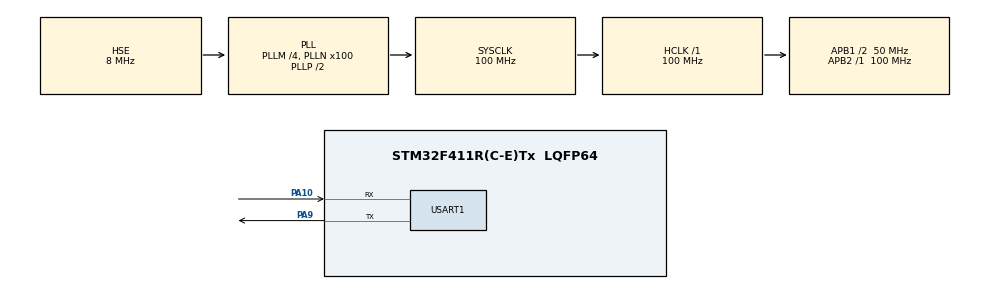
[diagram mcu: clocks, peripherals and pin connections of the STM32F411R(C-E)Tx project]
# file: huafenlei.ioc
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Mcu.Family=STM32F4
Mcu.Name=STM32F411R(C-E)Tx
Mcu.Package=LQFP64
NVIC.PriorityGroup=NVIC_PRIORITYGROUP_4
NVIC.USART1_IRQn=true\:0\:0\:false\:false\:true\:true\:true\:true
PA10.Mode=Asynchronous
PA10.Signal=USART1_RX
PA13.Mode=Serial_Wire
PA13.Signal=SYS_JTMS-SWDIO
PA14.Mode=Serial_Wire
PA14.Signal=SYS_JTCK-SWCLK
PA9.Mode=Asynchronous
PA9.Signal=USART1_TX
PH0\ -\ OSC_IN.Mode=HSE-External-Oscillator
PH0\ -\ OSC_IN.Signal=RCC_OSC_IN
PH1\ -\ OSC_OUT.Mode=HSE-External-Oscillator
PH1\ -\ OSC_OUT.Signal=RCC_OSC_OUT
ProjectManager.HeapSize=0x800
ProjectManager.StackSize=0x800
ProjectManager.TargetToolchain=MDK-ARM V5.27
RCC.48MHZClocksFreq_Value=50000000
RCC.AHBFreq_Value=100000000
RCC.APB1CLKDivider=RCC_HCLK_DIV2
RCC.APB1Freq_Value=50000000
RCC.APB1TimFreq_Value=100000000
RCC.APB2Freq_Value=100000000
RCC.APB2TimFreq_Value=100000000
RCC.CortexFreq_Value=100000000
RCC.HCLKFreq_Value=100000000
RCC.HSE_VALUE=8000000
RCC.HSI_VALUE=16000000
RCC.LSE_VALUE=32768
RCC.PLLM=4
RCC.PLLN=100
RCC.PLLSourceVirtual=RCC_PLLSOURCE_HSE
RCC.SYSCLKFreq_VALUE=100000000
RCC.SYSCLKSource=RCC_SYSCLKSOURCE_PLLCLK
RCC.VCOOutputFreq_Value=200000000
STMicroelectronics.X-CUBE-AI.10.2.0.ActivationBufferSizeList=2084
STMicroelectronics.X-CUBE-AI.10.2.0.ActivationBuffers=pool0
STMicroelectronics.X-CUBE-AI.10.2.0.ActivationNames=pool0
STMicroelectronics.X-CUBE-AI.10.2.0.ActivationSizes=AI_NETWORK_DATA_ACTIVATION_1_SIZE
STMicroelectronics.X-CUBE-AI.10.2.0.HeapSize=0x800
STMicroelectronics.X-CUBE-AI.10.2.0.InternalRamActivationBufferMaxSize=AI_NETWORK_DATA_ACTIVATIONS_SIZE
STMicroelectronics.X-CUBE-AI.10.2.0.LatestDirectoryUsed-87fcd24d699568835ba487657c0ed03bb26ed7f382c4cfd018235e4fa8d2ef7a=D\:\\
STMicroelectronics.X-CUBE-AI.10.2.0.MaximumNumberOfInputLayer=1
STMicroelectronics.X-CUBE-AI.10.2.0.MaximumNumberOfOutputLayer=1
STMicroelectronics.X-CUBE-AI.10.2.0.MaximumSizeOfInputLayer=1
STMicroelectronics.X-CUBE-AI.10.2.0.MaximumSizeOfOutputLayer=1
STMicroelectronics.X-CUBE-AI.10.2.0.ModelActualCompression-87fcd24d699568835ba487657c0ed03bb26ed7f382c4cfd018235e4fa8d2ef7a=0.0
STMicroelectronics.X-CUBE-AI.10.2.0.ModelCompression-87fcd24d699568835ba487657c0ed03bb26ed7f382c4cfd018235e4fa8d2ef7a=None
STMicroelectronics.X-CUBE-AI.10.2.0.ModelFlashOccupation-87fcd24d699568835ba487657c0ed03bb26ed7f382c4cfd018235e4fa8d2ef7a=11856
STMicroelectronics.X-CUBE-AI.10.2.0.ModelHashList=87fcd24d699568835ba487657c0ed03bb26ed7f382c4cfd018235e4fa8d2ef7a
STMicroelectronics.X-CUBE-AI.10.2.0.ModelKind-87fcd24d699568835ba487657c0ed03bb26ed7f382c4cfd018235e4fa8d2ef7a=ONNX
STMicroelectronics.X-CUBE-AI.10.2.0.ModelMacc-87fcd24d699568835ba487657c0ed03bb26ed7f382c4cfd018235e4fa8d2ef7a=312
STMicroelectronics.X-CUBE-AI.10.2.0.ModelName-87fcd24d699568835ba487657c0ed03bb26ed7f382c4cfd018235e4fa8d2ef7a=network
STMicroelectronics.X-CUBE-AI.10.2.0.ModelNameList=network
STMicroelectronics.X-CUBE-AI.10.2.0.ModelRamOccupation-87fcd24d699568835ba487657c0ed03bb26ed7f382c4cfd018235e4fa8d2ef7a=2084
STMicroelectronics.X-CUBE-AI.10.2.0.ModelStructureFile-87fcd24d699568835ba487657c0ed03bb26ed7f382c4cfd018235e4fa8d2ef7a=D\:\\iris.onnx
STMicroelectronics.X-CUBE-AI.10.2.0.ModelType-87fcd24d699568835ba487657c0ed03bb26ed7f382c4cfd018235e4fa8d2ef7a=STM32Cube.AI MCU runtime
STMicroelectronics.X-CUBE-AI.10.2.0.ReadyForCodeGeneration=true
STMicroelectronics.X-CUBE-AI.10.2.0.StackSize=0x800
STMicroelectronics.X-CUBE-AI.10.2.0.WorkingBufferStartAddrList=0xFFFFFFFF
STMicroelectronics.X-CUBE-AI.10.2.0.XAaCUBEAaAICcArtificialOoIntelligenceJjCore=true
STMicroelectronics.X-CUBE-AI.10.2.0.copyWeightToRam=false
STMicroelectronics.X-CUBE-AI.10.2.0.copyWeightToRam-87fcd24d699568835ba487657c0ed03bb26ed7f382c4cfd018235e4fa8d2ef7a=false
STMicroelectronics.X-CUBE-AI.10.2.0.customLayerConfigEnabled=false
STMicroelectronics.X-CUBE-AI.10.2.0.customLayerConfigEnabled-87fcd24d699568835ba487657c0ed03bb26ed7f382c4cfd018235e4fa8d2ef7a=false
STMicroelectronics.X-CUBE-AI.10.2.0.noOnnxIoTranspose=false
STMicroelectronics.X-CUBE-AI.10.2.0.noOnnxIoTranspose-87fcd24d699568835ba487657c0ed03bb26ed7f382c4cfd018235e4fa8d2ef7a=false
STMicroelectronics.X-CUBE-AI.10.2.0.useInputAllocation=true
STMicroelectronics.X-CUBE-AI.10.2.0.useInputAllocation-87fcd24d699568835ba487657c0ed03bb26ed7f382c4cfd018235e4fa8d2ef7a=true
STMicroelectronics.X-CUBE-AI.10.2.0.useOutputAllocation=true
STMicroelectronics.X-CUBE-AI.10.2.0.useOutputAllocation-87fcd24d699568835ba487657c0ed03bb26ed7f382c4cfd018235e4fa8d2ef7a=true
USART1.VirtualMode=VM_ASYNC
VP_STMicroelectronics.X-CUBE-AI_VS_ArtificialOoIntelligenceJjXAaCUBEAaAI_10.2.0.Mode=ArtificialOoIntelligenceJjXAaCUBEAaAI
board=custom

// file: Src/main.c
/* USER CODE BEGIN Header */
/**
  ******************************************************************************
  * @file           : main.c
  * @brief          : Main program body
  ******************************************************************************
  * @attention
  *
  * Copyright (c) 2026 STMicroelectronics.
  * All rights reserved.
  *
  * This software is licensed under terms that can be found in the LICENSE file
  * in the root directory of this software component.
  * If no LICENSE file comes with this software, it is provided AS-IS.
  *
  ******************************************************************************
  */
/* USER CODE END Header */
#include "main.h"
#include "usart.h"
#include "gpio.h"

/* USER CODE BEGIN PV */
#include <stdio.h>
#include <string.h>
#include <stdlib.h>
#include "network.h"
#include "network_data.h"
#include "network_data_params.h"

char rx_buf[50];

// ????,??????????? 96 ??
#if defined(__ICCARM__) || defined(__CC_ARM) || defined(__ARMCC_VERSION)
__align(4) float ai_input_data[4];
__align(4) float ai_output_data[3];
__align(4) uint8_t activations[96]; // <--- ??? 96
#else
float ai_input_data[4] __attribute__((aligned(4)));
float ai_output_data[3] __attribute__((aligned(4)));
uint8_t activations[96] __attribute__((aligned(4))); // <--- ??? 96
#endif

ai_handle network = AI_HANDLE_NULL;
/* USER CODE END PV */

void SystemClock_Config(void);

/* USER CODE BEGIN 0 */
int fputc(int ch, FILE *f)
{
    HAL_UART_Transmit(&huart1, (uint8_t *)&ch, 1, HAL_MAX_DELAY);
    return ch;
}
void AI_Init(void)
{
  // 1. ???? CRC
  __HAL_RCC_CRC_CLK_ENABLE();

  ai_error err;

  // 2. ??????
  err = ai_network_create(&network, AI_NETWORK_DATA_CONFIG);
  if (err.type != AI_ERROR_NONE)
  {
    printf("AI CREATE FAIL! TYPE: %d, CODE: %d\r\n", err.type, err.code);
    return;
  }

  // 3. ???????
  ai_network_params params;

  // 4. ?????????????????
  if (ai_network_data_params_get(&params) != true)
  {
     err = ai_network_get_error(network);
     printf("GET PARAMS FAIL! TYPE: %d, CODE: %d\r\n", err.type, err.code);
     return;
  }

  // 5. ???????????????????? activations ??
  // ???????:params ????? map_activations ????
  AI_BUFFER_ARRAY_ITEM_SET_ADDRESS(&params.map_activations, 0, activations);

  // 6. ????????????
  if (!ai_network_init(network, &params))
  {
    err = ai_network_get_error(network);
    printf("AI INIT FAIL! TYPE: %d, CODE: %d\r\n", err.type, err.code);
    return;
  }

  printf("AI INIT ALL SUCCESS !!!\r\n");
}
int AI_Run(float *in, float *out)
{
  // 1. ????????????,??????????????? buffer ??
  ai_buffer* ai_input_ptr  = ai_network_inputs_get(network, NULL);
  ai_buffer* ai_output_ptr = ai_network_outputs_get(network, NULL);

  if (ai_input_ptr != NULL && ai_output_ptr != NULL)
  {
    // 2. ??????????????????????
    ai_input_ptr[0].data  = AI_HANDLE_PTR(in);
    ai_output_ptr[0].data = AI_HANDLE_PTR(out);
  }
  else
  {
    printf("Error: Cannot get official AI buffers!\r\n");
    return 0;
  }

  // 3. ??????
  ai_network_run(network, ai_input_ptr, ai_output_ptr);

  // 4. ???????????
  int max_idx = 0;
  for(int i = 1; i < 3; i++)
  {
    if(out[i] > out[max_idx])
    {
      max_idx = i;
    }
  }
  return max_idx;
}
/* USER CODE END 0 */

int main(void)
{

  /* MCU Configuration--------------------------------------------------------*/

  /* Reset of all peripherals, Initializes the Flash interface and the Systick. */
  HAL_Init();

  /* Configure the system clock */
  SystemClock_Config();

  /* Initialize all configured peripherals */
  MX_GPIO_Init();
  MX_USART1_UART_Init();
  /* USER CODE BEGIN 2 */
AI_Init();
printf("Iris Ready\r\n");
  /* USER CODE END 2 */

  /* Infinite loop */
  /* USER CODE BEGIN WHILE */
	uint8_t ch;
  int rx_index = 0;
  memset(rx_buf, 0, sizeof(rx_buf));
  while (1)
  {

		if (HAL_UART_Receive(&huart1, &ch, 1, HAL_MAX_DELAY) == HAL_OK)
    {
      // ???????,????????,????
      if (ch == '\n' || ch == '\r')
      {
        if (rx_index > 0) // ?????????
        {
          rx_buf[rx_index] = '\0'; // ?????????

          // ???? AI ??
          if(sscanf(rx_buf, "%f,%f,%f,%f",
                    &ai_input_data[0],
                    &ai_input_data[1],
                    &ai_input_data[2],
                    &ai_input_data[3]) == 4)
          {
						printf(">> sscanf OK! Data: %.2f, %.2f\r\n", ai_input_data[0], ai_input_data[1]);
            int max_index = AI_Run(ai_input_data, ai_output_data);
						printf("Raw Output: [%.4f, %.4f, %.4f]\r\n", ai_output_data[0], ai_output_data[1], ai_output_data[2]);

            switch(max_index){
              case 0: printf("Setosa\r\n"); break;
              case 1: printf("Versicolor\r\n"); break;
              case 2: printf("Virginica\r\n"); break;
            }
          }

          // ????,????????,????
          rx_index = 0;
          memset(rx_buf, 0, sizeof(rx_buf));
        }
      }
      else
      {
        // ??????,??????????,?????????
        if (rx_index < sizeof(rx_buf) - 1)
        {
          rx_buf[rx_index++] = ch;
        }
        else
        {
          // ??????????????
          rx_index = 0;
          memset(rx_buf, 0, sizeof(rx_buf));
        }
      }
    }
    /* USER CODE END WHILE */

  }
}

void SystemClock_Config(void)
{
  RCC_OscInitTypeDef RCC_OscInitStruct = {0};
  RCC_ClkInitTypeDef RCC_ClkInitStruct = {0};

  /** Configure the main internal regulator output voltage
  */
  __HAL_RCC_PWR_CLK_ENABLE();
  __HAL_PWR_VOLTAGESCALING_CONFIG(PWR_REGULATOR_VOLTAGE_SCALE1);

  /** Initializes the RCC Oscillators according to the specified parameters
  * in the RCC_OscInitTypeDef structure.
  */
  RCC_OscInitStruct.OscillatorType = RCC_OSCILLATORTYPE_HSE;
  RCC_OscInitStruct.HSEState = RCC_HSE_ON;
  RCC_OscInitStruct.PLL.PLLState = RCC_PLL_ON;
  RCC_OscInitStruct.PLL.PLLSource = RCC_PLLSOURCE_HSE;
  RCC_OscInitStruct.PLL.PLLM = 4;
  RCC_OscInitStruct.PLL.PLLN = 100;
  RCC_OscInitStruct.PLL.PLLP = RCC_PLLP_DIV2;
  RCC_OscInitStruct.PLL.PLLQ = 4;
  if (HAL_RCC_OscConfig(&RCC_OscInitStruct) != HAL_OK)
  {
    Error_Handler();
  }

  /** Initializes the CPU, AHB and APB buses clocks
  */
  RCC_ClkInitStruct.ClockType = RCC_CLOCKTYPE_HCLK|RCC_CLOCKTYPE_SYSCLK
                              |RCC_CLOCKTYPE_PCLK1|RCC_CLOCKTYPE_PCLK2;
  RCC_ClkInitStruct.SYSCLKSource = RCC_SYSCLKSOURCE_PLLCLK;
  RCC_ClkInitStruct.AHBCLKDivider = RCC_SYSCLK_DIV1;
  RCC_ClkInitStruct.APB1CLKDivider = RCC_HCLK_DIV2;
  RCC_ClkInitStruct.APB2CLKDivider = RCC_HCLK_DIV1;

  if (HAL_RCC_ClockConfig(&RCC_ClkInitStruct, FLASH_LATENCY_3) != HAL_OK)
  {
    Error_Handler();
  }
}

void Error_Handler(void)
{
  __disable_irq();
  while (1)
  {
  }
}
